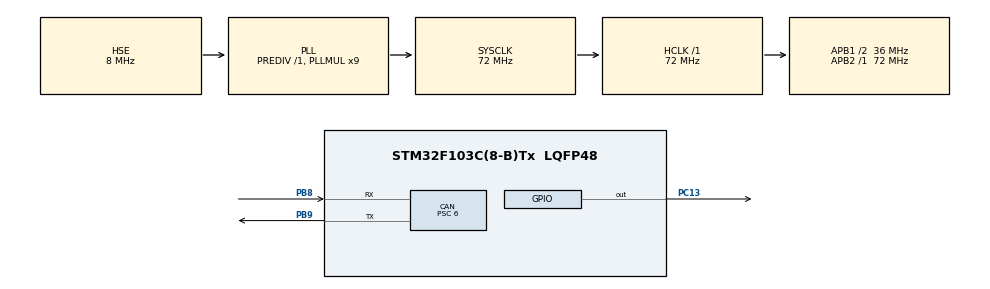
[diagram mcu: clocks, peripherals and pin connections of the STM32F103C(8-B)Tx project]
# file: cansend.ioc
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CAN.ABOM=ENABLE
CAN.BS1=CAN_BS1_8TQ
CAN.BS2=CAN_BS2_3TQ
CAN.CalculateTimeBit=2000
CAN.CalculateTimeQuantum=166.66666666666669
CAN.NART=DISABLE
CAN.Prescaler=6
CAN.SJW=CAN_SJW_1TQ
Mcu.Family=STM32F1
Mcu.Name=STM32F103C(8-B)Tx
Mcu.Package=LQFP48
NVIC.PriorityGroup=NVIC_PRIORITYGROUP_4
NVIC.TIM4_IRQn=true\:0\:0\:false\:false\:true\:false\:true
NVIC.TimeBase=TIM4_IRQn
NVIC.TimeBaseIP=TIM4
NVIC.USB_HP_CAN1_TX_IRQn=true\:0\:0\:false\:false\:true\:true\:true
NVIC.USB_LP_CAN1_RX0_IRQn=true\:0\:0\:false\:false\:true\:true\:true
PA13.Mode=Serial_Wire
PA13.Signal=SYS_JTMS-SWDIO
PA14.Mode=Serial_Wire
PA14.Signal=SYS_JTCK-SWCLK
PB8.Mode=Master
PB8.Signal=CAN_RX
PB9.Mode=Master
PB9.Signal=CAN_TX
PC13-TAMPER-RTC.Signal=GPIO_Output
PD0-OSC_IN.Mode=HSE-External-Oscillator
PD0-OSC_IN.Signal=RCC_OSC_IN
PD1-OSC_OUT.Mode=HSE-External-Oscillator
PD1-OSC_OUT.Signal=RCC_OSC_OUT
ProjectManager.HeapSize=0x200
ProjectManager.StackSize=0x400
ProjectManager.TargetToolchain=MDK-ARM V5
RCC.AHBFreq_Value=72000000
RCC.APB1CLKDivider=RCC_HCLK_DIV2
RCC.APB1Freq_Value=36000000
RCC.APB1TimFreq_Value=72000000
RCC.APB2Freq_Value=72000000
RCC.APB2TimFreq_Value=72000000
RCC.HCLKFreq_Value=72000000
RCC.PLLMUL=RCC_PLL_MUL9
RCC.PLLSourceVirtual=RCC_PLLSOURCE_HSE
RCC.SYSCLKFreq_VALUE=72000000
RCC.SYSCLKSource=RCC_SYSCLKSOURCE_PLLCLK
RCC.USBFreq_Value=48000000
RCC.USBPrescaler=RCC_USBCLKSOURCE_PLL_DIV1_5
VP_SYS_VS_tim4.Mode=TIM4
board=custom

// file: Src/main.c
/* USER CODE BEGIN Header */
/**
  ******************************************************************************
  * @file           : main.c
  * @brief          : Main program body
  ******************************************************************************
  * @attention
  *
  * <h2><center>&copy; Copyright (c) 2019 STMicroelectronics.
  * All rights reserved.</center></h2>
  *
  * This software component is licensed by ST under BSD 3-Clause license,
  * the "License"; You may not use this file except in compliance with the
  * License. You may obtain a copy of the License at:
  *                        opensource.org/licenses/BSD-3-Clause
  *
  ******************************************************************************
  */
/* USER CODE END Header */

#include "main.h"

CAN_HandleTypeDef hcan;

void SystemClock_Config(void);
static void MX_GPIO_Init(void);
static void MX_CAN_Init(void);

int main(void)
{

  /* MCU Configuration--------------------------------------------------------*/

  /* Reset of all peripherals, Initializes the Flash interface and the Systick. */
  HAL_Init();

  /* Configure the system clock */
  SystemClock_Config();

  /* Initialize all configured peripherals */
  MX_GPIO_Init();
  MX_CAN_Init();
  /* USER CODE BEGIN 2 */

	HAL_CAN_Start(&hcan);
	HAL_CAN_WakeUp(&hcan);
	HAL_CAN_ActivateNotification(&hcan,CAN_IT_RX_FIFO0_MSG_PENDING);

	CAN_FilterTypeDef filter;
	filter.FilterIdHigh=0xffff;
	filter.FilterIdLow=0x0000;
	filter.FilterFIFOAssignment=CAN_FILTER_FIFO0;
	filter.FilterScale=CAN_FILTERSCALE_16BIT;
	filter.FilterMode=CAN_FILTERMODE_IDMASK;

	filter.FilterActivation=CAN_FILTER_DISABLE;
	HAL_CAN_ConfigFilter(&hcan,&filter);

	CAN_RxHeaderTypeDef pck;
		pck.DLC=4;
		pck.StdId=0x234;
		pck.IDE=CAN_ID_STD;
		pck.RTR=CAN_RTR_DATA;
		pck.FilterMatchIndex=0xff;
  unsigned char data[4];

	uint32_t pt_fifo;
	HAL_StatusTypeDef a;
	/* USER CODE END 2 */
	/* Infinite loop */
  /* USER CODE BEGIN WHILE */
  while (1)
  {

			HAL_GPIO_TogglePin(GPIOC, GPIO_PIN_13);
			HAL_Delay(1000);

			a=HAL_CAN_GetRxMessage(&hcan,CAN_RX_FIFO0,&pck,data);

			//if(a==HAL_OK){
			HAL_GPIO_TogglePin(GPIOC, GPIO_PIN_13);
			HAL_Delay(50);//}

    /* USER CODE END WHILE */

  }
}

void SystemClock_Config(void)
{
  RCC_OscInitTypeDef RCC_OscInitStruct = {0};
  RCC_ClkInitTypeDef RCC_ClkInitStruct = {0};

  /** Initializes the CPU, AHB and APB busses clocks
  */
  RCC_OscInitStruct.OscillatorType = RCC_OSCILLATORTYPE_HSE;
  RCC_OscInitStruct.HSEState = RCC_HSE_ON;
  RCC_OscInitStruct.HSEPredivValue = RCC_HSE_PREDIV_DIV1;
  RCC_OscInitStruct.HSIState = RCC_HSI_ON;
  RCC_OscInitStruct.PLL.PLLState = RCC_PLL_ON;
  RCC_OscInitStruct.PLL.PLLSource = RCC_PLLSOURCE_HSE;
  RCC_OscInitStruct.PLL.PLLMUL = RCC_PLL_MUL9;
  if (HAL_RCC_OscConfig(&RCC_OscInitStruct) != HAL_OK)
  {
    Error_Handler();
  }
  /** Initializes the CPU, AHB and APB busses clocks
  */
  RCC_ClkInitStruct.ClockType = RCC_CLOCKTYPE_HCLK|RCC_CLOCKTYPE_SYSCLK
                              |RCC_CLOCKTYPE_PCLK1|RCC_CLOCKTYPE_PCLK2;
  RCC_ClkInitStruct.SYSCLKSource = RCC_SYSCLKSOURCE_PLLCLK;
  RCC_ClkInitStruct.AHBCLKDivider = RCC_SYSCLK_DIV1;
  RCC_ClkInitStruct.APB1CLKDivider = RCC_HCLK_DIV2;
  RCC_ClkInitStruct.APB2CLKDivider = RCC_HCLK_DIV1;

  if (HAL_RCC_ClockConfig(&RCC_ClkInitStruct, FLASH_LATENCY_2) != HAL_OK)
  {
    Error_Handler();
  }
}

static void MX_CAN_Init(void)
{

  hcan.Instance = CAN1;
  hcan.Init.Prescaler = 6;
  hcan.Init.Mode = CAN_MODE_NORMAL;
  hcan.Init.SyncJumpWidth = CAN_SJW_1TQ;
  hcan.Init.TimeSeg1 = CAN_BS1_8TQ;
  hcan.Init.TimeSeg2 = CAN_BS2_3TQ;
  hcan.Init.TimeTriggeredMode = DISABLE;
  hcan.Init.AutoBusOff = ENABLE;
  hcan.Init.AutoWakeUp = DISABLE;
  hcan.Init.AutoRetransmission = DISABLE;
  hcan.Init.ReceiveFifoLocked = DISABLE;
  hcan.Init.TransmitFifoPriority = DISABLE;
  if (HAL_CAN_Init(&hcan) != HAL_OK)
  {
    Error_Handler();
  }

}

static void MX_GPIO_Init(void)
{
  GPIO_InitTypeDef GPIO_InitStruct = {0};

  /* GPIO Ports Clock Enable */
  __HAL_RCC_GPIOC_CLK_ENABLE();
  __HAL_RCC_GPIOD_CLK_ENABLE();
  __HAL_RCC_GPIOA_CLK_ENABLE();
  __HAL_RCC_GPIOB_CLK_ENABLE();

  /*Configure GPIO pin Output Level */
  HAL_GPIO_WritePin(GPIOC, GPIO_PIN_13, GPIO_PIN_RESET);

  /*Configure GPIO pin : PC13 */
  GPIO_InitStruct.Pin = GPIO_PIN_13;
  GPIO_InitStruct.Mode = GPIO_MODE_OUTPUT_PP;
  GPIO_InitStruct.Pull = GPIO_NOPULL;
  GPIO_InitStruct.Speed = GPIO_SPEED_FREQ_LOW;
  HAL_GPIO_Init(GPIOC, &GPIO_InitStruct);

}

/* USER CODE BEGIN 4 */

void HAL_CAN_RxFifo0MsgPendingCallback(CAN_HandleTypeDef *hcan)
{

	HAL_GPIO_TogglePin(GPIOC, GPIO_PIN_13);
	HAL_Delay(50);
}

/* USER CODE END 4 */

void HAL_TIM_PeriodElapsedCallback(TIM_HandleTypeDef *htim)
{
  if (htim->Instance == TIM4) {
    HAL_IncTick();
  }
}

void Error_Handler(void)
{
}

/************************ (C) COPYRIGHT STMicroelectronics *****END OF FILE****/
